# STM32U585 register map
File version: 2.2
CPU: CM33 r0p1, little endian, MPU, FPU, 4 interrupt priority bits
Registers are 32-bit, read-write, reset 0x0 unless marked. A register's access mark holds for its fields unless they carry their own. Offsets are from the block's base; [hi:lo] are bit positions.

## TIM6 — General-purpose-timers
Base 0x40001000
Same registers: TIM7 0x40001400, SEC_TIM6 0x50001000, SEC_TIM7 0x50001400
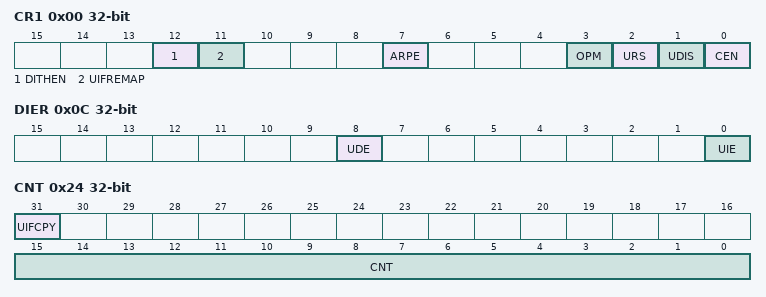
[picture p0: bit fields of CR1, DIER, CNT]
0x00 CR1 — control register 1
  [12] DITHEN — Dithering Enable
  [11] UIFREMAP — UIF status bit remapping
  [7] ARPE — Auto-reload preload enable
  [3] OPM — One-pulse mode
  [2] URS — Update request source
  [1] UDIS — Update disable
  [0] CEN — Counter enable
0x04 CR2 — control register 2
  [6:4] MMS — Master mode selection
0x0C DIER — DMA/Interrupt enable register
  [8] UDE, [0] UIE
0x10 SR — status register
  [0] UIF
0x14 EGR wo — event generation register
  [0] UG
0x24 CNT — counter
  [31] UIFCPY, [15:0] CNT
0x28 PSC — prescaler
  [15:0] PSC
0x2C ARR reset 0xFFFF — auto-reload register
  [19:0] ARR

## WWDG — System window watchdog
Base 0x40002C00
Same registers: SEC_WWDG 0x50002C00
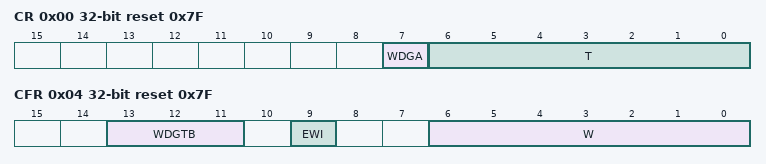
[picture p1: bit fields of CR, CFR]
0x00 CR reset 0x7F — Control register
  [7] WDGA — Activation bit
  [6:0] T — 7-bit counter (MSB to LSB)
0x04 CFR reset 0x7F — Configuration register
  [13:11] WDGTB — Timer base
  [9] EWI — Early wakeup interrupt
  [6:0] W — 7-bit window value
0x08 SR — Status register
  [0] EWIF — Early wakeup interrupt

## PKA — Private key accelerator
Base 0x420C2000
Same registers: SEC_PKA 0x520C2000
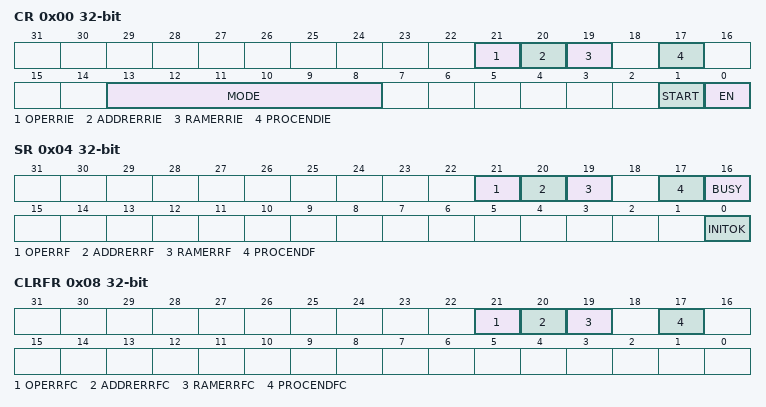
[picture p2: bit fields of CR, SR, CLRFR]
0x00 CR — Control register
  [21] OPERRIE — Operation error interrupt enable
  [20] ADDRERRIE — Address error interrupt
  [19] RAMERRIE — RAM error interrupt enable
  [17] PROCENDIE — End of operation interrupt
  [13:8] MODE — PKA Operation Mode
  [1] START — Start the operation
  [0] EN — Peripheral Enable
0x04 SR ro — PKA status register
  [21] OPERRF
  [20] ADDRERRF
  [19] RAMERRF
  [17] PROCENDF — PKA End of Operation flag
  [16] BUSY — PKA operation is in
  [0] INITOK
0x08 CLRFR wo — PKA clear flag register
  [21] OPERRFC
  [20] ADDRERRFC
  [19] RAMERRFC
  [17] PROCENDFC — Clear PKA End of Operation

## LPUART1 — Universal synchronous asynchronous receiver
Base 0x46002400
Same registers: SEC_LPUART1 0x56002400
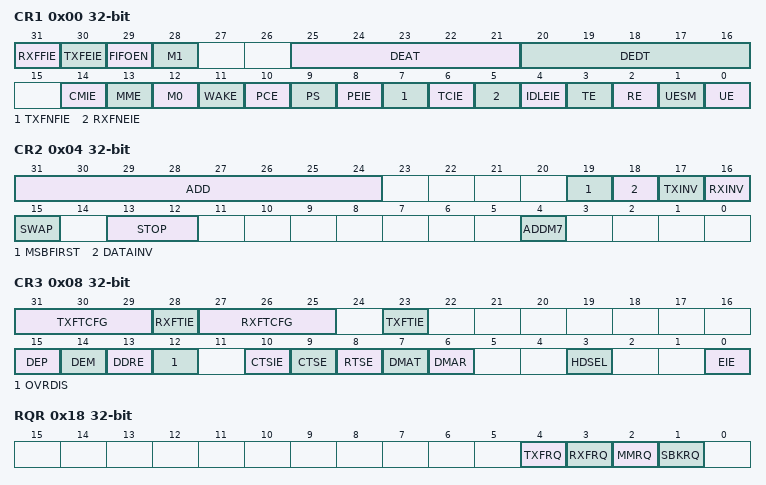
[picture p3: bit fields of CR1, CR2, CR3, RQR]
0x00 CR1 — Control register 1
  [31] RXFFIE
  [30] TXFEIE
  [29] FIFOEN
  [28] M1 — Word length
  [25:21] DEAT
  [20:16] DEDT
  [14] CMIE — Character match interrupt
  [13] MME — Mute mode enable
  [12] M0 — Word length
  [11] WAKE — Receiver wakeup method
  [10] PCE — Parity control enable
  [9] PS — Parity selection
  [8] PEIE — PE interrupt enable
  [7] TXFNFIE — TXFIFO not full interrupt enable
  [6] TCIE — Transmission complete interrupt
  [5] RXFNEIE
  [4] IDLEIE — IDLE interrupt enable
  [3] TE — Transmitter enable
  [2] RE — Receiver enable
  [1] UESM — USART enable in Stop mode
  [0] UE — USART enable
0x04 CR2 — Control register 2
  [31:24] ADD — Address of the LPUART node
  [19] MSBFIRST — Most significant bit first
  [18] DATAINV — Binary data inversion
  [17] TXINV — TX pin active level
  [16] RXINV — RX pin active level
  [15] SWAP — Swap TX/RX pins
  [13:12] STOP — STOP bits
  [4] ADDM7 — 7-bit Address Detection/4-bit Address
0x08 CR3 — Control register 3
  [31:29] TXFTCFG
  [28] RXFTIE
  [27:25] RXFTCFG
  [23] TXFTIE
  [15] DEP — Driver enable polarity
  [14] DEM — Driver enable mode
  [13] DDRE — DMA Disable on Reception
  [12] OVRDIS — Overrun Disable
  [10] CTSIE — CTS interrupt enable
  [9] CTSE — CTS enable
  [8] RTSE — RTS enable
  [7] DMAT — DMA enable transmitter
  [6] DMAR — DMA enable receiver
  [3] HDSEL — Half-duplex selection
  [0] EIE — Error interrupt enable
0x0C BRR — Baud rate register
  [19:0] BRR
0x18 RQR wo — Request register
  [4] TXFRQ
  [3] RXFRQ — Receive data flush request
  [2] MMRQ — Mute mode request
  [1] SBKRQ — Send break request
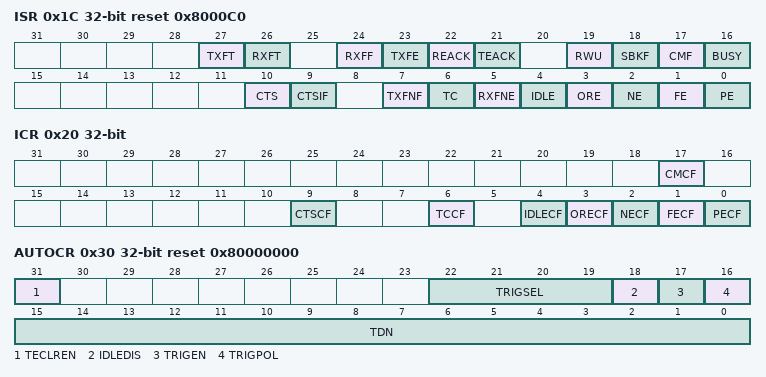
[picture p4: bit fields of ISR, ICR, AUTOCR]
0x1C ISR ro reset 0x8000C0 — Interrupt and status register
  [27] TXFT, [26] RXFT, [24] RXFF, [23] TXFE, [22] REACK, [21] TEACK, [19] RWU, [18] SBKF, [17] CMF, [16] BUSY, [10] CTS, [9] CTSIF, [7] TXFNF, [6] TC, [5] RXFNE, [4] IDLE, [3] ORE, [2] NE, [1] FE, [0] PE
0x20 ICR wo — Interrupt flag clear register
  [17] CMCF — Character match clear flag
  [9] CTSCF — CTS clear flag
  [6] TCCF — Transmission complete clear
  [4] IDLECF — Idle line detected clear
  [3] ORECF — Overrun error clear flag
  [2] NECF — Noise detected clear flag
  [1] FECF — Framing error clear flag
  [0] PECF — Parity error clear flag
0x24 RDR ro — Receive data register
  [8:0] RDR — Receive data value
0x28 TDR — Transmit data register
  [8:0] TDR — Transmit data value
0x2C PRESC — prescaler register
  [3:0] PRESCALER
0x30 AUTOCR reset 0x80000000 — Autonomous mode control register
  [31] TECLREN, [22:19] TRIGSEL, [18] IDLEDIS, [17] TRIGEN, [16] TRIGPOL, [15:0] TDN
